# LM3S2678 register map
File version: 7944
Registers are 32-bit, read-write, no defined reset value unless marked. A register's access mark holds for its fields unless they carry their own. Offsets are from the block's base; [hi:lo] are bit positions; {n}, {i} and the like mark numbered series.

## PWM0 — Register map for PWM0 peripheral
Base 0x40028000; register names take the prefix PWM0
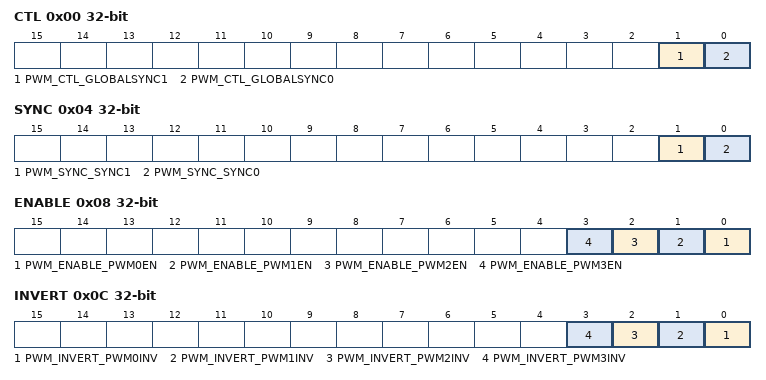
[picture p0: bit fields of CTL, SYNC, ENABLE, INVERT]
0x00 CTL — PWM Master Control
  [1] PWM_CTL_GLOBALSYNC1 — Update PWM Generator 1
  [0] PWM_CTL_GLOBALSYNC0 — Update PWM Generator 0
0x04 SYNC — PWM Time Base Sync
  [1] PWM_SYNC_SYNC1 — Reset Generator 1 Counter
  [0] PWM_SYNC_SYNC0 — Reset Generator 0 Counter
0x08 ENABLE — PWM Output Enable
  [n] PWM_ENABLE_PWM{n}EN (n=0..3) — PWM{n} Output Enable
0x0C INVERT — PWM Output Inversion
  [n] PWM_INVERT_PWM{n}INV (n=0..3) — Invert PWM{n} Signal
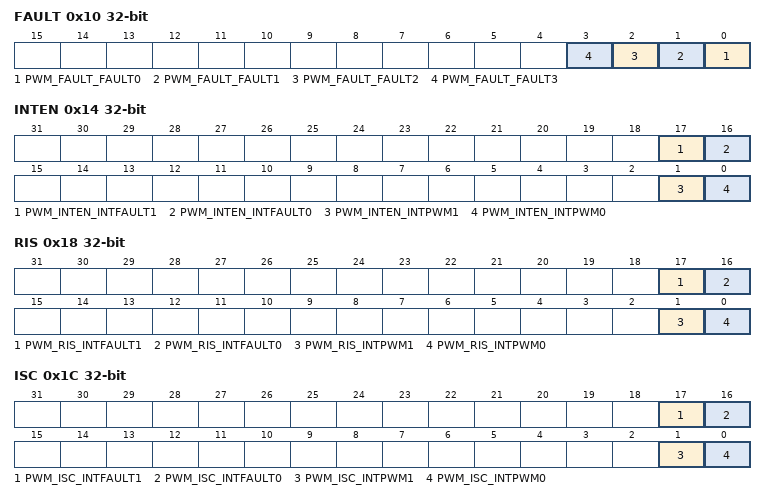
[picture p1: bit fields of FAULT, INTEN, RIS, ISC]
0x10 FAULT — PWM Output Fault
  [n] PWM_FAULT_FAULT{n} (n=0..3) — PWM{n} Fault
0x14 INTEN — PWM Interrupt Enable
  [17] PWM_INTEN_INTFAULT1 — Interrupt Fault 1
  [16] PWM_INTEN_INTFAULT0 — Interrupt Fault 0
  [1] PWM_INTEN_INTPWM1 — PWM1 Interrupt Enable
  [0] PWM_INTEN_INTPWM0 — PWM0 Interrupt Enable
0x18 RIS — PWM Raw Interrupt Status
  [17] PWM_RIS_INTFAULT1 — Interrupt Fault PWM 1
  [16] PWM_RIS_INTFAULT0 — Interrupt Fault PWM 0
  [1] PWM_RIS_INTPWM1 — PWM1 Interrupt Asserted
  [0] PWM_RIS_INTPWM0 — PWM0 Interrupt Asserted
0x1C ISC — PWM Interrupt Status and Clear
  [17] PWM_ISC_INTFAULT1 — FAULT1 Interrupt Asserted
  [16] PWM_ISC_INTFAULT0 — FAULT0 Interrupt Asserted
  [1] PWM_ISC_INTPWM1 — PWM1 Interrupt Status
  [0] PWM_ISC_INTPWM0 — PWM0 Interrupt Status
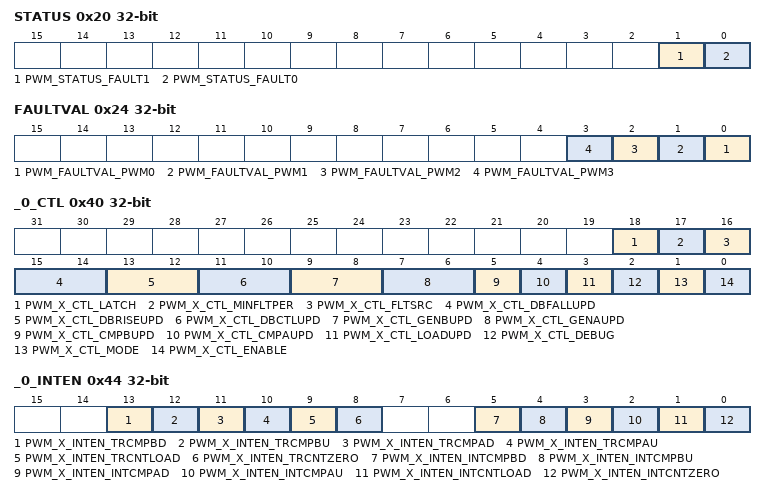
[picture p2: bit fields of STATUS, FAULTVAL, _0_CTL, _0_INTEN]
0x20 STATUS — PWM Status
  [1] PWM_STATUS_FAULT1 — Generator 1 Fault Status
  [0] PWM_STATUS_FAULT0 — Generator 0 Fault Status
0x24 FAULTVAL — PWM Fault Condition Value
  [n] PWM_FAULTVAL_PWM{n} (n=0..3) — PWM{n} Fault Value
0x40 _0_CTL — PWM0 Control
  [18] PWM_X_CTL_LATCH — Latch Fault Input
  [17] PWM_X_CTL_MINFLTPER — Minimum Fault Period
  [16] PWM_X_CTL_FLTSRC — Fault Condition Source
  [15:14] PWM_X_CTL_DBFALLUPD — PWMnDBFALL Update Mode
    0=PWM_X_CTL_DBFALLUPD_I (Immediate); 2=PWM_X_CTL_DBFALLUPD_LS (Locally Synchronized); 3=PWM_X_CTL_DBFALLUPD_GS (Globally Synchronized)
  [13:12] PWM_X_CTL_DBRISEUPD — PWMnDBRISE Update Mode
    0=PWM_X_CTL_DBRISEUPD_I (Immediate); 2=PWM_X_CTL_DBRISEUPD_LS (Locally Synchronized); 3=PWM_X_CTL_DBRISEUPD_GS (Globally Synchronized)
  [11:10] PWM_X_CTL_DBCTLUPD — PWMnDBCTL Update Mode
    0=PWM_X_CTL_DBCTLUPD_I (Immediate); 2=PWM_X_CTL_DBCTLUPD_LS (Locally Synchronized); 3=PWM_X_CTL_DBCTLUPD_GS (Globally Synchronized)
  [9:8] PWM_X_CTL_GENBUPD — PWMnGENB Update Mode
    0=PWM_X_CTL_GENBUPD_I (Immediate); 2=PWM_X_CTL_GENBUPD_LS (Locally Synchronized); 3=PWM_X_CTL_GENBUPD_GS (Globally Synchronized)
  [7:6] PWM_X_CTL_GENAUPD — PWMnGENA Update Mode
    0=PWM_X_CTL_GENAUPD_I (Immediate); 2=PWM_X_CTL_GENAUPD_LS (Locally Synchronized); 3=PWM_X_CTL_GENAUPD_GS (Globally Synchronized)
  [5] PWM_X_CTL_CMPBUPD — Comparator B Update Mode
  [4] PWM_X_CTL_CMPAUPD — Comparator A Update Mode
  [3] PWM_X_CTL_LOADUPD — Load Register Update Mode
  [2] PWM_X_CTL_DEBUG — Debug Mode
  [1] PWM_X_CTL_MODE — Counter Mode
  [0] PWM_X_CTL_ENABLE — PWM Block Enable
0x44 _0_INTEN — PWM0 Interrupt and Trigger Enable
  [13] PWM_X_INTEN_TRCMPBD — Trigger for Counter=PWMnCMPB Down
  [12] PWM_X_INTEN_TRCMPBU — Trigger for Counter=PWMnCMPB Up
  [11] PWM_X_INTEN_TRCMPAD — Trigger for Counter=PWMnCMPA Down
  [10] PWM_X_INTEN_TRCMPAU — Trigger for Counter=PWMnCMPA Up
  [9] PWM_X_INTEN_TRCNTLOAD — Trigger for Counter=PWMnLOAD
  [8] PWM_X_INTEN_TRCNTZERO — Trigger for Counter=0
  [5] PWM_X_INTEN_INTCMPBD — Interrupt for Counter=PWMnCMPB Down
  [4] PWM_X_INTEN_INTCMPBU — Interrupt for Counter=PWMnCMPB Up
  [3] PWM_X_INTEN_INTCMPAD — Interrupt for Counter=PWMnCMPA Down
  [2] PWM_X_INTEN_INTCMPAU — Interrupt for Counter=PWMnCMPA Up
  [1] PWM_X_INTEN_INTCNTLOAD — Interrupt for Counter=PWMnLOAD
  [0] PWM_X_INTEN_INTCNTZERO — Interrupt for Counter=0
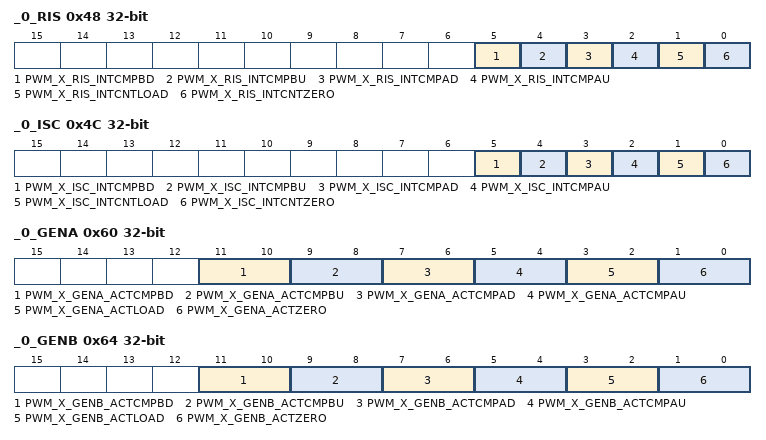
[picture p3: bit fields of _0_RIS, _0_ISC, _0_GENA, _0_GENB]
0x48 _0_RIS — PWM0 Raw Interrupt Status
  [5] PWM_X_RIS_INTCMPBD — Comparator B Down Interrupt Status
  [4] PWM_X_RIS_INTCMPBU — Comparator B Up Interrupt Status
  [3] PWM_X_RIS_INTCMPAD — Comparator A Down Interrupt Status
  [2] PWM_X_RIS_INTCMPAU — Comparator A Up Interrupt Status
  [1] PWM_X_RIS_INTCNTLOAD — Counter=Load Interrupt Status
  [0] PWM_X_RIS_INTCNTZERO — Counter=0 Interrupt Status
0x4C _0_ISC — PWM0 Interrupt Status and Clear
  [5] PWM_X_ISC_INTCMPBD — Comparator B Down Interrupt
  [4] PWM_X_ISC_INTCMPBU — Comparator B Up Interrupt
  [3] PWM_X_ISC_INTCMPAD — Comparator A Down Interrupt
  [2] PWM_X_ISC_INTCMPAU — Comparator A Up Interrupt
  [1] PWM_X_ISC_INTCNTLOAD — Counter=Load Interrupt
  [0] PWM_X_ISC_INTCNTZERO — Counter=0 Interrupt
0x50 _0_LOAD — PWM0 Load
  [15:0] PWM_X_LOAD — Counter Load Value
0x54 _0_COUNT — PWM0 Counter
  [15:0] PWM_X_COUNT — Counter Value
0x58 _0_CMPA — PWM0 Compare A
  [15:0] PWM_X_CMPA — Comparator A Value
0x5C _0_CMPB — PWM0 Compare B
  [15:0] PWM_X_CMPB — Comparator B Value
0x60 _0_GENA — PWM0 Generator A Control
  [11:10] PWM_X_GENA_ACTCMPBD — Action for Comparator B Down
    0=PWM_X_GENA_ACTCMPBD_NONE (Do nothing); 1=PWM_X_GENA_ACTCMPBD_INV (Invert pwmA); 2=PWM_X_GENA_ACTCMPBD_ZERO (Drive pwmA Low); 3=PWM_X_GENA_ACTCMPBD_ONE (Drive pwmA High)
  [9:8] PWM_X_GENA_ACTCMPBU — Action for Comparator B Up
    0=PWM_X_GENA_ACTCMPBU_NONE (Do nothing); 1=PWM_X_GENA_ACTCMPBU_INV (Invert pwmA); 2=PWM_X_GENA_ACTCMPBU_ZERO (Drive pwmA Low); 3=PWM_X_GENA_ACTCMPBU_ONE (Drive pwmA High)
  [7:6] PWM_X_GENA_ACTCMPAD — Action for Comparator A Down
    0=PWM_X_GENA_ACTCMPAD_NONE (Do nothing); 1=PWM_X_GENA_ACTCMPAD_INV (Invert pwmA); 2=PWM_X_GENA_ACTCMPAD_ZERO (Drive pwmA Low); 3=PWM_X_GENA_ACTCMPAD_ONE (Drive pwmA High)
  [5:4] PWM_X_GENA_ACTCMPAU — Action for Comparator A Up
    0=PWM_X_GENA_ACTCMPAU_NONE (Do nothing); 1=PWM_X_GENA_ACTCMPAU_INV (Invert pwmA); 2=PWM_X_GENA_ACTCMPAU_ZERO (Drive pwmA Low); 3=PWM_X_GENA_ACTCMPAU_ONE (Drive pwmA High)
  [3:2] PWM_X_GENA_ACTLOAD — Action for Counter=LOAD
    0=PWM_X_GENA_ACTLOAD_NONE (Do nothing); 1=PWM_X_GENA_ACTLOAD_INV (Invert pwmA); 2=PWM_X_GENA_ACTLOAD_ZERO (Drive pwmA Low); 3=PWM_X_GENA_ACTLOAD_ONE (Drive pwmA High)
  [1:0] PWM_X_GENA_ACTZERO — Action for Counter=0
    0=PWM_X_GENA_ACTZERO_NONE (Do nothing); 1=PWM_X_GENA_ACTZERO_INV (Invert pwmA); 2=PWM_X_GENA_ACTZERO_ZERO (Drive pwmA Low); 3=PWM_X_GENA_ACTZERO_ONE (Drive pwmA High)
0x64 _0_GENB — PWM0 Generator B Control
  [11:10] PWM_X_GENB_ACTCMPBD — Action for Comparator B Down
    0=PWM_X_GENB_ACTCMPBD_NONE (Do nothing); 1=PWM_X_GENB_ACTCMPBD_INV (Invert pwmB); 2=PWM_X_GENB_ACTCMPBD_ZERO (Drive pwmB Low); 3=PWM_X_GENB_ACTCMPBD_ONE (Drive pwmB High)
  [9:8] PWM_X_GENB_ACTCMPBU — Action for Comparator B Up
    0=PWM_X_GENB_ACTCMPBU_NONE (Do nothing); 1=PWM_X_GENB_ACTCMPBU_INV (Invert pwmB); 2=PWM_X_GENB_ACTCMPBU_ZERO (Drive pwmB Low); 3=PWM_X_GENB_ACTCMPBU_ONE (Drive pwmB High)
  [7:6] PWM_X_GENB_ACTCMPAD — Action for Comparator A Down
    0=PWM_X_GENB_ACTCMPAD_NONE (Do nothing); 1=PWM_X_GENB_ACTCMPAD_INV (Invert pwmB); 2=PWM_X_GENB_ACTCMPAD_ZERO (Drive pwmB Low); 3=PWM_X_GENB_ACTCMPAD_ONE (Drive pwmB High)
  [5:4] PWM_X_GENB_ACTCMPAU — Action for Comparator A Up
    0=PWM_X_GENB_ACTCMPAU_NONE (Do nothing); 1=PWM_X_GENB_ACTCMPAU_INV (Invert pwmB); 2=PWM_X_GENB_ACTCMPAU_ZERO (Drive pwmB Low); 3=PWM_X_GENB_ACTCMPAU_ONE (Drive pwmB High)
  [3:2] PWM_X_GENB_ACTLOAD — Action for Counter=LOAD
    0=PWM_X_GENB_ACTLOAD_NONE (Do nothing); 1=PWM_X_GENB_ACTLOAD_INV (Invert pwmB); 2=PWM_X_GENB_ACTLOAD_ZERO (Drive pwmB Low); 3=PWM_X_GENB_ACTLOAD_ONE (Drive pwmB High)
  [1:0] PWM_X_GENB_ACTZERO — Action for Counter=0
    0=PWM_X_GENB_ACTZERO_NONE (Do nothing); 1=PWM_X_GENB_ACTZERO_INV (Invert pwmB); 2=PWM_X_GENB_ACTZERO_ZERO (Drive pwmB Low); 3=PWM_X_GENB_ACTZERO_ONE (Drive pwmB High)
0x68 _0_DBCTL — PWM0 Dead-Band Control
  [0] PWM_X_DBCTL_ENABLE — Dead-Band Generator Enable
0x6C _0_DBRISE — PWM0 Dead-Band Rising-Edge Delay
  [11:0] PWM_X_DBRISE_DELAY — Dead-Band Rise Delay
0x70 _0_DBFALL — PWM0 Dead-Band Falling-Edge-Delay
  [11:0] PWM_X_DBFALL_DELAY — Dead-Band Fall Delay
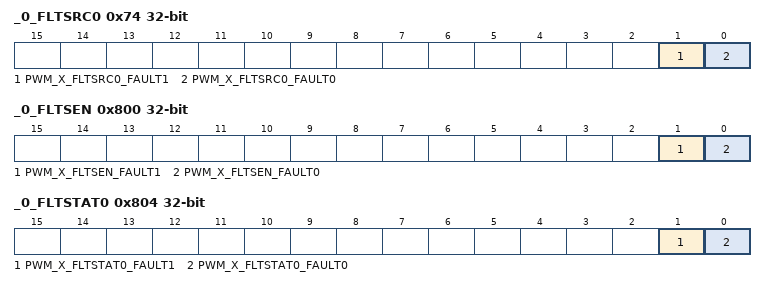
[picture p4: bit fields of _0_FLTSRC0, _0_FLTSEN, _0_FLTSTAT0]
0x74 _0_FLTSRC0 — PWM0 Fault Source 0
  [1] PWM_X_FLTSRC0_FAULT1 — Fault1 Input
  [0] PWM_X_FLTSRC0_FAULT0 — Fault0 Input
0x7C _0_MINFLTPER — PWM0 Minimum Fault Period
  [15:0] PWM_X_MINFLTPER — Minimum Fault Period
0x80 _1_CTL — PWM1 Control
0x84 _1_INTEN — PWM1 Interrupt and Trigger Enable
0x88 _1_RIS — PWM1 Raw Interrupt Status
0x8C _1_ISC — PWM1 Interrupt Status and Clear
0x90 _1_LOAD — PWM1 Load
0x94 _1_COUNT — PWM1 Counter
0x98 _1_CMPA — PWM1 Compare A
0x9C _1_CMPB — PWM1 Compare B
0xA0 _1_GENA — PWM1 Generator A Control
0xA4 _1_GENB — PWM1 Generator B Control
0xA8 _1_DBCTL — PWM1 Dead-Band Control
0xAC _1_DBRISE — PWM1 Dead-Band Rising-Edge Delay
0xB0 _1_DBFALL — PWM1 Dead-Band Falling-Edge-Delay
0xB4 _1_FLTSRC0 — PWM1 Fault Source 0
0xBC _1_MINFLTPER — PWM1 Minimum Fault Period
0x800 _0_FLTSEN — PWM0 Fault Pin Logic Sense
  [1] PWM_X_FLTSEN_FAULT1 — Fault1 Sense
  [0] PWM_X_FLTSEN_FAULT0 — Fault0 Sense
0x804 _0_FLTSTAT0 ro — PWM0 Fault Status 0
  [1] PWM_X_FLTSTAT0_FAULT1 — Fault Input 1
  [0] PWM_X_FLTSTAT0_FAULT0 — Fault Input 0
0x880 _1_FLTSEN — PWM1 Fault Pin Logic Sense
0x884 _1_FLTSTAT0 ro — PWM1 Fault Status 0
